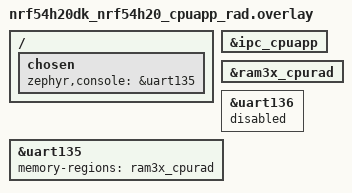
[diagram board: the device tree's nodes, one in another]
/*
 * Copyright (c) 2022 Nordic Semiconductor ASA
 *
 * SPDX-License-Identifier: Apache-2.0
 */

#include <common/nordic_nrf_next/nrfx_ram3x_dma.dtsi>
#include "../../boards/shared/nrf54_uart_pinout.dtsi"

/{
	chosen {
		zephyr,console = &uart135;
	};
};

ipc0: &ipc_cpuapp { };

&ram3x_cpurad {
	status = "okay";
};

&uart136 {
	status = "disabled";
};

&uart135 {
	status = "okay";
	memory-regions = <&ram3x_cpurad>;
};
